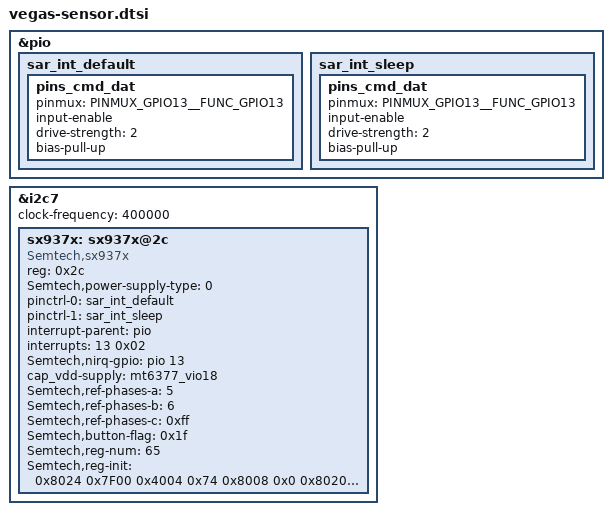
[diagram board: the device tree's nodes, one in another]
/*
 * Copyright (c) 2019 MediaTek Inc.
 *
 * This program is free software; you can redistribute it and/or modify
 * it under the terms of the GNU General Public License version 2 as
 * published by the Free Software Foundation.
 *
 * This program is distributed in the hope that it will be useful,
 * but WITHOUT ANY WARRANTY; without even the implied warranty of
 * MERCHANTABILITY or FITNESS FOR A PARTICULAR PURPOSE.  See the
 * GNU General Public License for more details.
 */

&pio {
	sar_int_default: sar_int_default {
		pins_cmd_dat {
			pinmux = <PINMUX_GPIO13__FUNC_GPIO13>;
			input-enable;
			drive-strength = <2>;
			bias-pull-up;
		};
	};

	sar_int_sleep: sar_int_sleep {
		pins_cmd_dat {
			pinmux = <PINMUX_GPIO13__FUNC_GPIO13>;
			input-enable;
			drive-strength = <2>;
			bias-pull-up;
		};
	};
};


&i2c7 {
	status = "okay";
	clock-frequency = <400000>;
	sx937x:sx937x@2c {
		compatible = "Semtech,sx937x";
		reg = <0x2c>;
		Semtech,power-supply-type = <0>;
		pinctrl-names = "default","sleep";
		pinctrl-0 = <&sar_int_default>;
		pinctrl-1 = <&sar_int_sleep>;
		interrupt-parent = <&pio>;
		interrupts = <13 0x02>;
		interrupt-names = "sx937x_irq";
		Semtech,nirq-gpio = <&pio 13 0x02>;
		cap_vdd-supply = <&mt6377_vio18>;
		/*use PH4/5/6 as the reference sensor
		set it to 0xff if the ref-phases-x is not used*/
		Semtech,ref-phases-a = <5>;
		Semtech,ref-phases-b = <6>;
		Semtech,ref-phases-c = <0xff>;
		Semtech,button-flag = <0x1f>;
		Semtech,reg-num = <65>;
		Semtech,reg-init = <
				0x8024 0x7F00
				0x4004 0x74
				0x8008 0x0
				0x8020 0x32
				0x8028 0x877
				0x8034 0x877
				0x8040 0x876
				0x804C 0x87F
				0x8058 0x877
				0x8064 0x876
				0x8070 0x876
				0x807C 0x876
				0x8030 0x924925
				0x803C 0x925924
				0x8048 0x92C924
				0x8054 0x964924
				0x8060 0xB24924
				0x806C 0x92492C
				0x8078 0x924964
				0x8084 0x0
				0x8098 0x6E33
				0x80B8 0x6969
				0x80D8 0x2929
				0x80F8 0x3030
				0x8118 0x572D
				0x8138 0xFF
				0x8158 0xFF
				0x8178 0x0
				0x80A0 0x20200001
				0x80C0 0x40400000
				0x80E0 0x0E0E0002
				0x8100 0x20200001
				0x8120 0x30300002
				0x8140 0x0
				0x8160 0x0
				0x8180 0x0
				0x8188 0x8000015
				0x818C 0x8000016
				0x8190 0x0
				0x8194 0x0
				0x8090 0x10005000
				0x80B0 0x04005000
				0x80D0 0x08005000
				0x80F0 0x08005000
				0x8110 0x08005000
				0x8130 0x5300
				0x8150 0x5300
				0x8170 0x5300
				0x8088 0x300000
				0x80A8 0x300000
				0x80C8 0x300000
				0x80E8 0x300000
				0x8108 0x300000
				0x8128 0x300000
				0x8148 0x300000
				0x8168 0x0
				0x808C 0x60200064
				0x80AC 0x60200064
				0x80CC 0x60200064
				0x80EC 0x60200064
				0x810C 0x60200064
				0x812C 0x60200030
				0x814C 0x60200030
				0x816C 0x0
				0x8024 0x7F7F
		>;

		status = "okay";
	};
};
